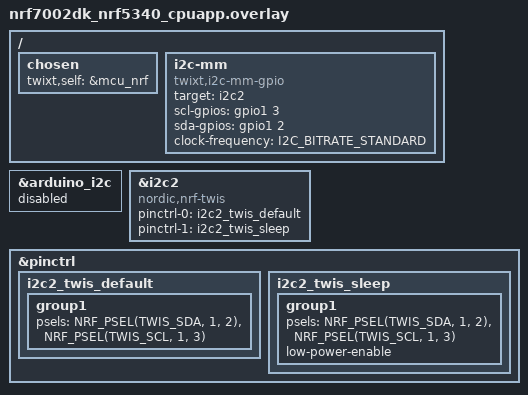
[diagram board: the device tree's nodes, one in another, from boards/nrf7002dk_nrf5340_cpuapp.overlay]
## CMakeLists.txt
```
# Copyright (c) 2026 Christoph Jans <jans.christoph@gmail.com>
# SPDX-License-Identifier: Apache-2.0

cmake_minimum_required(VERSION 3.20.0)

# native_sim: MCU says which one this is. Real boards: the overlay.
set(MCU pico CACHE STRING "MCU to build on native_sim: pico or nrf")
list(APPEND DTS_EXTRA_CPPFLAGS -DTWIXT_SELF_LABEL=mcu_${MCU})

find_package(Zephyr REQUIRED HINTS $ENV{ZEPHYR_BASE})
project(twixt_service)

target_sources(app PRIVATE src/main.c)
target_sources_ifdef(CONFIG_USB_DEVICE_STACK_NEXT app PRIVATE src/usb.c)
```

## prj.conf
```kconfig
# Copyright (c) 2026 Christoph Jans <jans.christoph@gmail.com>
# SPDX-License-Identifier: Apache-2.0

CONFIG_I2C=y
CONFIG_LOG=y
CONFIG_LOG_BACKEND_SHOW_COLOR=n
```

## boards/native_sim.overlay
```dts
/*
 * Copyright (c) 2026 Christoph Jans <jans.christoph@gmail.com>
 *
 * SPDX-License-Identifier: Apache-2.0
 */

/ {
	chosen {
		twixt,self = &TWIXT_SELF_LABEL;
	};
};

&i2c0 {
	compatible = "twixt,i2c-mm-native";
	bus-id = <6>;

#include "../twixt_mcus.dtsi"
};
```

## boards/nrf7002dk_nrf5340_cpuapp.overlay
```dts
/*
 * Copyright (c) 2026 Christoph Jans <jans.christoph@gmail.com>
 *
 * SPDX-License-Identifier: Apache-2.0
 */

/* The bus on the Arduino SDA P1.02, SCL P1.03, at 1.8 V: TWIS2 is the target, the controller
 * software on the same pins (twixt,i2c-mm-gpio), as the TWIM cannot detect lost arbitration.
 */

#include <zephyr/dt-bindings/i2c/i2c.h>

/ {
	chosen {
		twixt,self = &mcu_nrf;
	};

	i2c-mm {
		compatible = "twixt,i2c-mm-gpio";
		target = <&i2c2>;
		scl-gpios = <&gpio1 3 0>;
		sda-gpios = <&gpio1 2 0>;
		clock-frequency = <I2C_BITRATE_STANDARD>;
		#address-cells = <1>;
		#size-cells = <0>;

#include "../twixt_mcus.dtsi"
	};
};

&arduino_i2c {
	status = "disabled";
};

&i2c2 {
	compatible = "nordic,nrf-twis";
	status = "okay";
	pinctrl-0 = <&i2c2_twis_default>;
	pinctrl-1 = <&i2c2_twis_sleep>;
	pinctrl-names = "default", "sleep";
};

&pinctrl {
	i2c2_twis_default: i2c2_twis_default {
		group1 {
			psels = <NRF_PSEL(TWIS_SDA, 1, 2)>,
				<NRF_PSEL(TWIS_SCL, 1, 3)>;
		};
	};

	i2c2_twis_sleep: i2c2_twis_sleep {
		group1 {
			psels = <NRF_PSEL(TWIS_SDA, 1, 2)>,
				<NRF_PSEL(TWIS_SCL, 1, 3)>;
			low-power-enable;
		};
	};
};
```

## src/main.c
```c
/*
 * Copyright (c) 2026 Christoph Jans <jans.christoph@gmail.com>
 *
 * SPDX-License-Identifier: Apache-2.0
 *
 * A service of your own (TWIXT_SERVICE_APP): two MCUs, both serve "add", and
 * each asks the other for a sum.
 *
 *     request:  int32 a, int32 b (little endian)
 *     response: int32 a + b
 */

#include <zephyr/kernel.h>
#include <zephyr/logging/log.h>
#include <zephyr/sys/byteorder.h>

#include <twixt/twixt.h>
#include <twixt/service/ping.h>

LOG_MODULE_REGISTER(service_sample, LOG_LEVEL_INF);

#define ADD_SERVICE TWIXT_SERVICE_APP

#define PEER                                                                                       \
	(twixt_self_addr() == DT_REG_ADDR(DT_NODELABEL(mcu_pico))                                  \
		 ? DT_REG_ADDR(DT_NODELABEL(mcu_nrf))                                              \
		 : DT_REG_ADDR(DT_NODELABEL(mcu_pico)))

/* Runs in the I2C target interrupt: short, no waiting */
static int add(const struct twixt_req *req, uint8_t *rsp_data)
{
	if (req->len != 8) {
		return -EINVAL;
	}
	sys_put_le32(sys_get_le32(&req->data[0]) + sys_get_le32(&req->data[4]), rsp_data);
	return 4;
}

TWIXT_SERVICE_DEFINE(add_service, ADD_SERVICE, add);

static int add_on(uint8_t addr, int32_t a, int32_t b, int32_t *sum)
{
	uint8_t req[8];
	uint8_t rsp[4];
	int ret;

	sys_put_le32(a, &req[0]);
	sys_put_le32(b, &req[4]);
	ret = twixt_request(addr, ADD_SERVICE, req, sizeof(req), rsp, sizeof(rsp));
	if (ret == 0) {
		*sum = sys_get_le32(rsp);
	}
	return ret;
}

int main(void)
{
	bool is_pico = twixt_self_addr() == DT_REG_ADDR(DT_NODELABEL(mcu_pico));
	int32_t a = is_pico ? 2 : 40;
	int32_t b = is_pico ? 3 : 2;
	struct twixt_ping_info info;
	int32_t sum;
	int ret;

	for (;; k_sleep(K_SECONDS(2))) {
		ret = twixt_ping_wait(PEER, &info, K_SECONDS(5));
		if (ret == 0) {
			ret = add_on(PEER, a, b, &sum);
		}
		if (ret) {
			LOG_ERR("0x%02x: %d", PEER, ret);
			continue;
		}
		LOG_INF("0x%02x adds %d + %d = %d", PEER, a, b, sum);
	}
	return 0;
}
```
